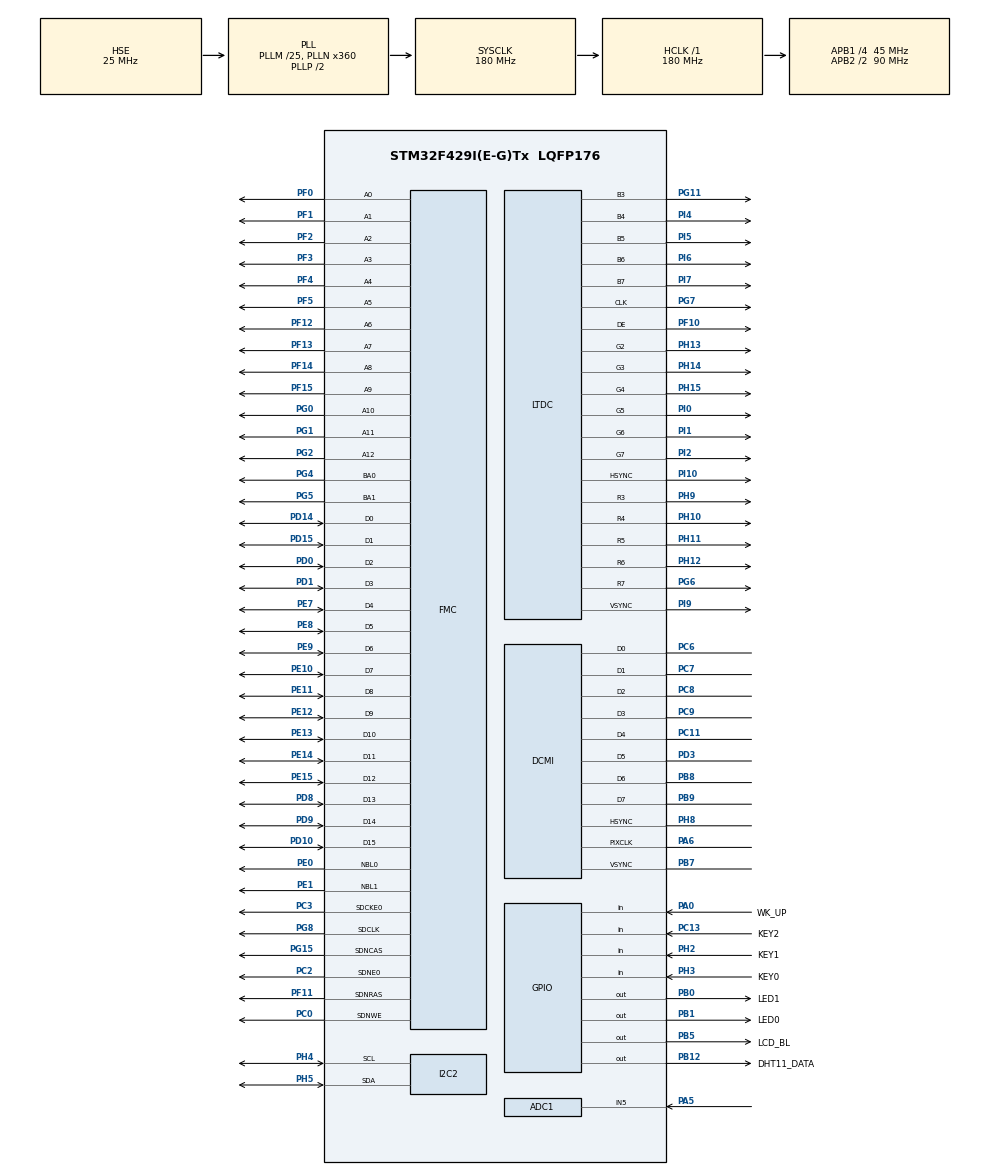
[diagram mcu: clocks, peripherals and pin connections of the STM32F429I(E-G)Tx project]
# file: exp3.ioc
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ADC1.Channel-1\#ChannelRegularConversion=ADC_CHANNEL_5
ADC1.NbrOfConversionFlag=1
ADC1.Rank-1\#ChannelRegularConversion=1
ADC1.SamplingTime-1\#ChannelRegularConversion=ADC_SAMPLETIME_480CYCLES
ADC1.master=1
DCMI.CaptureRate=DCMI_CR_ALL_FRAME
DCMI.HSPolarity=DCMI_HSPOLARITY_LOW
DCMI.PCKPolarity=DCMI_PCKPOLARITY_RISING
DCMI.VSPolarity=DCMI_VSPOLARITY_LOW
Dma.DCMI.0.Direction=DMA_PERIPH_TO_MEMORY
Dma.DCMI.0.FIFOMode=DMA_FIFOMODE_ENABLE
Dma.DCMI.0.FIFOThreshold=DMA_FIFO_THRESHOLD_FULL
Dma.DCMI.0.Instance=DMA2_Stream1
Dma.DCMI.0.MemBurst=DMA_MBURST_SINGLE
Dma.DCMI.0.MemDataAlignment=DMA_MDATAALIGN_HALFWORD
Dma.DCMI.0.MemInc=DMA_MINC_ENABLE
Dma.DCMI.0.Mode=DMA_CIRCULAR
Dma.DCMI.0.PeriphBurst=DMA_PBURST_SINGLE
Dma.DCMI.0.PeriphDataAlignment=DMA_PDATAALIGN_WORD
Dma.DCMI.0.PeriphInc=DMA_PINC_DISABLE
Dma.DCMI.0.Priority=DMA_PRIORITY_HIGH
Dma.Request0=DCMI
FMC.CASLatency1=FMC_SDRAM_CAS_LATENCY_2
FMC.ColumnBitsNumber1=FMC_SDRAM_COLUMN_BITS_NUM_9
FMC.ExitSelfRefreshDelay1=7
FMC.LoadToActiveDelay1=2
FMC.RCDDelay1=2
FMC.RPDelay1=2
FMC.ReadBurst1=FMC_SDRAM_RBURST_ENABLE
FMC.RowBitsNumber1=FMC_SDRAM_ROW_BITS_NUM_13
FMC.RowCycleDelay1=6
FMC.SDClockPeriod1=FMC_SDRAM_CLOCK_PERIOD_2
FMC.SelfRefreshTime1=6
FMC.WriteRecoveryTime1=4
LTDC.ActiveH=600
LTDC.ActiveW=1024
LTDC.Alpha_L0=255
LTDC.FBStartAdress_L0=0xC0000000
LTDC.HBP=140
LTDC.HFP=160
LTDC.HSync=20
LTDC.ImageHeight_L0=600
LTDC.ImageWidth_L0=1024
LTDC.Layers=0
LTDC.PCPolarity=LTDC_PCPOLARITY_IPC
LTDC.PixelFormat_L0=LTDC_PIXEL_FORMAT_RGB565
LTDC.VBP=20
LTDC.VFP=12
LTDC.VSync=3
LTDC.WindowX1_L0=1024
LTDC.WindowY1_L0=600
Mcu.Family=STM32F4
Mcu.Name=STM32F429I(E-G)Tx
Mcu.Package=LQFP176
NVIC.DCMI_IRQn=true\:2\:2\:false\:false\:true\:true\:true\:true
NVIC.DMA2_Stream1_IRQn=true\:1\:1\:false\:false\:true\:true\:true\:true
NVIC.PriorityGroup=NVIC_PRIORITYGROUP_4
PA0/WKUP.GPIO_Label=WK_UP
PA0/WKUP.GPIO_PuPd=GPIO_PULLDOWN
PA0/WKUP.Signal=GPIO_Input
PA13.Mode=Serial_Wire
PA13.Signal=SYS_JTMS-SWDIO
PA14.Mode=Serial_Wire
PA14.Signal=SYS_JTCK-SWCLK
PA5.Signal=ADCx_IN5
PA6.Mode=Slave_8_bits_External_Synchro
PA6.Signal=DCMI_PIXCLK
PB0.GPIO_Label=LED1
PB0.PinState=GPIO_PIN_SET
PB0.Signal=GPIO_Output
PB1.GPIO_Label=LED0
PB1.PinState=GPIO_PIN_SET
PB1.Signal=GPIO_Output
PB12.GPIO_Label=DHT11_DATA
PB12.GPIO_ModeDefaultOutputPP=GPIO_MODE_OUTPUT_OD
PB12.GPIO_PuPd=GPIO_NOPULL
PB12.GPIO_Speed=GPIO_SPEED_FREQ_HIGH
PB12.PinState=GPIO_PIN_SET
PB12.Signal=GPIO_Output
PB5.GPIO_Label=LCD_BL
PB5.PinState=GPIO_PIN_SET
PB5.Signal=GPIO_Output
PB7.Mode=Slave_8_bits_External_Synchro
PB7.Signal=DCMI_VSYNC
PB8.Mode=Slave_8_bits_External_Synchro
PB8.Signal=DCMI_D6
PB9.Mode=Slave_8_bits_External_Synchro
PB9.Signal=DCMI_D7
PC0.Signal=FMC_SDNWE
PC11.Mode=Slave_8_bits_External_Synchro
PC11.Signal=DCMI_D4
PC13.GPIO_Label=KEY2
PC13.GPIO_PuPd=GPIO_PULLUP
PC13.Signal=GPIO_Input
PC2.Mode=SdramChipSelect1_1
PC2.Signal=FMC_SDNE0
PC3.Mode=SdramChipSelect1_1
PC3.Signal=FMC_SDCKE0
PC6.Mode=Slave_8_bits_External_Synchro
PC6.Signal=DCMI_D0
PC7.Mode=Slave_8_bits_External_Synchro
PC7.Signal=DCMI_D1
PC8.Mode=Slave_8_bits_External_Synchro
PC8.Signal=DCMI_D2
PC9.Mode=Slave_8_bits_External_Synchro
PC9.Signal=DCMI_D3
PD0.Signal=FMC_D2_DA2
PD1.Signal=FMC_D3_DA3
PD10.Signal=FMC_D15_DA15
PD14.Signal=FMC_D0_DA0
PD15.Signal=FMC_D1_DA1
PD3.Mode=Slave_8_bits_External_Synchro
PD3.Signal=DCMI_D5
PD8.Signal=FMC_D13_DA13
PD9.Signal=FMC_D14_DA14
PE0.Signal=FMC_NBL0
PE1.Signal=FMC_NBL1
PE10.Signal=FMC_D7_DA7
PE11.Signal=FMC_D8_DA8
PE12.Signal=FMC_D9_DA9
PE13.Signal=FMC_D10_DA10
PE14.Signal=FMC_D11_DA11
PE15.Signal=FMC_D12_DA12
PE7.Signal=FMC_D4_DA4
PE8.Signal=FMC_D5_DA5
PE9.Signal=FMC_D6_DA6
PF0.Signal=FMC_A0
PF1.Signal=FMC_A1
PF10.Mode=RGB565
PF10.Signal=LTDC_DE
PF11.Signal=FMC_SDNRAS
PF12.Signal=FMC_A6
PF13.Signal=FMC_A7
PF14.Signal=FMC_A8
PF15.Signal=FMC_A9
PF2.Signal=FMC_A2
PF3.Signal=FMC_A3
PF4.Signal=FMC_A4
PF5.Signal=FMC_A5
PG0.Signal=FMC_A10
PG1.Signal=FMC_A11
PG11.Mode=RGB565
PG11.Signal=LTDC_B3
PG15.Signal=FMC_SDNCAS
PG2.Signal=FMC_A12
PG4.Signal=FMC_A14_BA0
PG5.Signal=FMC_A15_BA1
PG6.Mode=RGB565
PG6.Signal=LTDC_R7
PG7.Mode=RGB565
PG7.Signal=LTDC_CLK
PG8.Signal=FMC_SDCLK
PH0/OSC_IN.Mode=HSE-External-Oscillator
PH0/OSC_IN.Signal=RCC_OSC_IN
PH1/OSC_OUT.Mode=HSE-External-Oscillator
PH1/OSC_OUT.Signal=RCC_OSC_OUT
PH10.Mode=RGB565
PH10.Signal=LTDC_R4
PH11.Mode=RGB565
PH11.Signal=LTDC_R5
PH12.Mode=RGB565
PH12.Signal=LTDC_R6
PH13.Mode=RGB565
PH13.Signal=LTDC_G2
PH14.Mode=RGB565
PH14.Signal=LTDC_G3
PH15.Mode=RGB565
PH15.Signal=LTDC_G4
PH2.GPIO_Label=KEY1
PH2.GPIO_PuPd=GPIO_PULLUP
PH2.Signal=GPIO_Input
PH3.GPIO_Label=KEY0
PH3.GPIO_PuPd=GPIO_PULLUP
PH3.Signal=GPIO_Input
PH4.Mode=I2C
PH4.Signal=I2C2_SCL
PH5.Mode=I2C
PH5.Signal=I2C2_SDA
PH8.Mode=Slave_8_bits_External_Synchro
PH8.Signal=DCMI_HSYNC
PH9.Mode=RGB565
PH9.Signal=LTDC_R3
PI0.Mode=RGB565
PI0.Signal=LTDC_G5
PI1.Mode=RGB565
PI1.Signal=LTDC_G6
PI10.Mode=RGB565
PI10.Signal=LTDC_HSYNC
PI2.Mode=RGB565
PI2.Signal=LTDC_G7
PI4.Mode=RGB565
PI4.Signal=LTDC_B4
PI5.Mode=RGB565
PI5.Signal=LTDC_B5
PI6.Mode=RGB565
PI6.Signal=LTDC_B6
PI7.Mode=RGB565
PI7.Signal=LTDC_B7
PI9.Mode=RGB565
PI9.Signal=LTDC_VSYNC
ProjectManager.HeapSize=0x200
ProjectManager.StackSize=0x400
ProjectManager.TargetToolchain=STM32CubeIDE
RCC.48MHZClocksFreq_Value=90000000
RCC.AHBFreq_Value=180000000
RCC.APB1CLKDivider=RCC_HCLK_DIV4
RCC.APB1Freq_Value=45000000
RCC.APB1TimFreq_Value=90000000
RCC.APB2CLKDivider=RCC_HCLK_DIV2
RCC.APB2Freq_Value=90000000
RCC.APB2TimFreq_Value=180000000
RCC.CortexFreq_Value=180000000
RCC.HCLKFreq_Value=180000000
RCC.HSE_VALUE=25000000
RCC.HSI_VALUE=16000000
RCC.LSE_VALUE=32768
RCC.PLLM=25
RCC.PLLN=360
RCC.PLLSAIDivR=RCC_PLLSAIDIVR_4
RCC.PLLSAIN=360
RCC.PLLSAIR=2
RCC.PLLSourceVirtual=RCC_PLLSOURCE_HSE
RCC.SYSCLKFreq_VALUE=180000000
RCC.SYSCLKSource=RCC_SYSCLKSOURCE_PLLCLK
RCC.VCOOutputFreq_Value=360000000
SH.ADCx_IN5.0=ADC1_IN5,IN5
SH.FMC_A0.0=FMC_A0,13b-sda1
SH.FMC_A1.0=FMC_A1,13b-sda1
SH.FMC_A10.0=FMC_A10,13b-sda1
SH.FMC_A11.0=FMC_A11,13b-sda1
SH.FMC_A12.0=FMC_A12,13b-sda1
SH.FMC_A14_BA0.0=FMC_BA0,FourSdramBanks1
SH.FMC_A15_BA1.0=FMC_BA1,FourSdramBanks1
SH.FMC_A2.0=FMC_A2,13b-sda1
SH.FMC_A3.0=FMC_A3,13b-sda1
SH.FMC_A4.0=FMC_A4,13b-sda1
SH.FMC_A5.0=FMC_A5,13b-sda1
SH.FMC_A6.0=FMC_A6,13b-sda1
SH.FMC_A7.0=FMC_A7,13b-sda1
SH.FMC_A8.0=FMC_A8,13b-sda1
SH.FMC_A9.0=FMC_A9,13b-sda1
SH.FMC_D0_DA0.0=FMC_D0,sd-16b-d1
SH.FMC_D10_DA10.0=FMC_D10,sd-16b-d1
SH.FMC_D11_DA11.0=FMC_D11,sd-16b-d1
SH.FMC_D12_DA12.0=FMC_D12,sd-16b-d1
SH.FMC_D13_DA13.0=FMC_D13,sd-16b-d1
SH.FMC_D14_DA14.0=FMC_D14,sd-16b-d1
SH.FMC_D15_DA15.0=FMC_D15,sd-16b-d1
SH.FMC_D1_DA1.0=FMC_D1,sd-16b-d1
SH.FMC_D2_DA2.0=FMC_D2,sd-16b-d1
SH.FMC_D3_DA3.0=FMC_D3,sd-16b-d1
SH.FMC_D4_DA4.0=FMC_D4,sd-16b-d1
SH.FMC_D5_DA5.0=FMC_D5,sd-16b-d1
SH.FMC_D6_DA6.0=FMC_D6,sd-16b-d1
SH.FMC_D7_DA7.0=FMC_D7,sd-16b-d1
SH.FMC_D8_DA8.0=FMC_D8,sd-16b-d1
SH.FMC_D9_DA9.0=FMC_D9,sd-16b-d1
SH.FMC_NBL0.0=FMC_NBL0,Sd2ByteEnable1
SH.FMC_NBL1.0=FMC_NBL1,Sd2ByteEnable1
SH.FMC_SDCLK.0=FMC_SDCLK,13b-sda1
SH.FMC_SDNCAS.0=FMC_SDNCAS,13b-sda1
SH.FMC_SDNRAS.0=FMC_SDNRAS,13b-sda1
SH.FMC_SDNWE.0=FMC_SDNWE,13b-sda1
board=custom

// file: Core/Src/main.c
/* USER CODE BEGIN Header */
/**
  ******************************************************************************
  * @file           : main.c
  * @brief          : Main program body
  ******************************************************************************
  * @attention
  *
  * Copyright (c) 2026 STMicroelectronics.
  * All rights reserved.
  *
  * This software is licensed under terms that can be found in the LICENSE file
  * in the root directory of this software component.
  * If no LICENSE file comes with this software, it is provided AS-IS.
  *
  ******************************************************************************
  */
/* USER CODE END Header */
#include "main.h"

/* USER CODE BEGIN Includes */
#include "lcd.h"
#include "lcd_ui.h"
#include "dht11.h"
#include "adc_volt.h"
#include "key.h"
#include "alert.h"
#include "camera.h"
/* USER CODE END Includes */

ADC_HandleTypeDef hadc1;

DCMI_HandleTypeDef hdcmi;
DMA_HandleTypeDef hdma_dcmi;

I2C_HandleTypeDef hi2c2;

LTDC_HandleTypeDef hltdc;

SDRAM_HandleTypeDef hsdram1;

/* USER CODE BEGIN PV */
static dht11_data_t g_dht;          /* DHT11 温湿度(整数/小数分离) */
static uint8_t      g_dht_ok = 0;   /* 最近一次 DHT11 读取是否成功 */
static uint8_t      g_page   = 0;   /* 0=首页, 1=摄像头预览 */
static uint8_t      g_cam_ok = 0;   /* 摄像头初始化是否成功 */
/* USER CODE END PV */

void SystemClock_Config(void);
static void MX_GPIO_Init(void);
static void MX_DMA_Init(void);
static void MX_DCMI_Init(void);
static void MX_I2C2_Init(void);
static void MX_FMC_Init(void);
static void MX_ADC1_Init(void);
static void MX_LTDC_Init(void);

int main(void)
{

  /* MCU Configuration--------------------------------------------------------*/

  /* Reset of all peripherals, Initializes the Flash interface and the Systick. */
  HAL_Init();

  /* Configure the system clock */
  SystemClock_Config();

  /* Initialize all configured peripherals */
  MX_GPIO_Init();
  MX_DMA_Init();
  MX_DCMI_Init();
  MX_I2C2_Init();
  MX_FMC_Init();
  MX_ADC1_Init();
  MX_LTDC_Init();
  /* USER CODE BEGIN 2 */
  /* ===== 初始化所有模块 ===== */
  lcd_init();                       /* 点亮背光 + 清屏 */
  dht11_init();
  adc_volt_init();
  key_init();
  alert_init();

  lcd_ui_init();                    /* 画首页固定文字(标题/设备标识/标签) */

  /* 摄像头初始化(失败不影响首页); 采集在切到摄像头页时启动 */
  g_cam_ok = (camera_init() == CAM_ERR_NONE);
  /* USER CODE END 2 */

  /* Infinite loop */
  while (1)
  {

    /* USER CODE BEGIN 3 */
    uint8_t key = key_scan();

    /* KEY0 切页 */
    if (key == KEY0)
    {
        g_page = !g_page;
        if (g_page)
        {
            /* 进入摄像头页: 启动采集, 画面逐行自动写入 LCD */
            if (g_cam_ok)
            {
                camera_start();
            }
            else
            {
                lcd_clear(WHITE);
                /* 故障提示用 ASCII: 中文字库只含界面固定用语, 写中文会因缺字而整行空白 */
                lcd_show_string(376, 200, 32, (char *)"CAMERA INIT FAILED", RED);
            }
        }
        else
        {
            camera_stop();          /* 停止采集, 避免覆盖首页 */
            lcd_ui_init();          /* 回到首页, 重画固定文字 */
        }
    }

    if (g_page == 0)
    {
        /* ===== 首页: 温湿度 + 电压 + 预警 ===== */
        uint32_t mv;
        uint16_t raw;
        static uint32_t last_dht = 0;

        /* DHT11 约 1s 读一次(采样间隔要求 >=1s) */
        if (HAL_GetTick() - last_dht >= 1000)
        {
            last_dht = HAL_GetTick();
            g_dht_ok = (dht11_read(&g_dht) == 0);
        }

        /* ADC 电压(取 8 次平均) */
        raw = adc_volt_raw_avg(8);
        mv  = adc_volt_mv(raw);

        /* 阈值预警: temp/humi 转 0.1 度/0.1%RH 整数 */
        int16_t t10 = (int16_t)(g_dht.temp_int * 10 + g_dht.temp_dec);
        int16_t h10 = (int16_t)(g_dht.humi_int * 10 + g_dht.humi_dec);
        alert_poll(t10, g_dht_ok, h10, g_dht_ok, mv, 1);

        /* 刷新首页数值区(局部刷新, 不闪) */
        {
            static char cam_stat[16];
            if (g_cam_ok) {
                cam_stat[0] = 'O'; cam_stat[1] = 'K'; cam_stat[2] = 0;
            } else if (g_cam_err == 2) {
                /* F2: 完整诊断串 "P<PCF> D<diag> I<id>"
                 *   P: PCF8574 读回值(FB=成功拉低PWDN, FF=未拉低, EE=读失败)
                 *   D: SCCB诊断(bit0=空闲SCL高,bit1=空闲SDA高,bit2=地址有ACK)
                 *   I: 读回的 OV5640 ID(应=5640) */
                static const char hex[] = "0123456789ABCDEF";
                cam_stat[0] = 'P';
                cam_stat[1] = hex[(g_cam_pcf >> 4) & 0xF];
                cam_stat[2] = hex[g_cam_pcf & 0xF];
                cam_stat[3] = ' ';
                cam_stat[4] = 'D';
                cam_stat[5] = '0' + (g_sccb_diag & 0x07);
                cam_stat[6] = ' ';
                cam_stat[7] = 'I';
                cam_stat[8]  = hex[(g_cam_id >> 12) & 0xF];
                cam_stat[9]  = hex[(g_cam_id >> 8) & 0xF];
                cam_stat[10] = hex[(g_cam_id >> 4) & 0xF];
                cam_stat[11] = hex[g_cam_id & 0xF];
                cam_stat[12] = 0;
            } else {
                cam_stat[0] = 'F'; cam_stat[1] = '0' + g_cam_err; cam_stat[2] = 0;
            }
            lcd_ui_update(g_dht_ok ? &g_dht : 0, mv, raw,
                          g_dht_ok, cam_stat, alert_get());
        }

        HAL_Delay(100);
    }
    else
    {
        /* ===== 摄像头预览页 ===== */
        HAL_Delay(50);
    }
  }
  /* USER CODE END 3 */
}

void SystemClock_Config(void)
{
  RCC_OscInitTypeDef RCC_OscInitStruct = {0};
  RCC_ClkInitTypeDef RCC_ClkInitStruct = {0};

  /** Configure the main internal regulator output voltage
  */
  __HAL_RCC_PWR_CLK_ENABLE();
  __HAL_PWR_VOLTAGESCALING_CONFIG(PWR_REGULATOR_VOLTAGE_SCALE1);

  /** Initializes the RCC Oscillators according to the specified parameters
  * in the RCC_OscInitTypeDef structure.
  */
  RCC_OscInitStruct.OscillatorType = RCC_OSCILLATORTYPE_HSE;
  RCC_OscInitStruct.HSEState = RCC_HSE_ON;
  RCC_OscInitStruct.PLL.PLLState = RCC_PLL_ON;
  RCC_OscInitStruct.PLL.PLLSource = RCC_PLLSOURCE_HSE;
  RCC_OscInitStruct.PLL.PLLM = 25;
  RCC_OscInitStruct.PLL.PLLN = 360;
  RCC_OscInitStruct.PLL.PLLP = RCC_PLLP_DIV2;
  RCC_OscInitStruct.PLL.PLLQ = 4;
  if (HAL_RCC_OscConfig(&RCC_OscInitStruct) != HAL_OK)
  {
    Error_Handler();
  }

  /** Activate the Over-Drive mode
  */
  if (HAL_PWREx_EnableOverDrive() != HAL_OK)
  {
    Error_Handler();
  }

  /** Initializes the CPU, AHB and APB buses clocks
  */
  RCC_ClkInitStruct.ClockType = RCC_CLOCKTYPE_HCLK|RCC_CLOCKTYPE_SYSCLK
                              |RCC_CLOCKTYPE_PCLK1|RCC_CLOCKTYPE_PCLK2;
  RCC_ClkInitStruct.SYSCLKSource = RCC_SYSCLKSOURCE_PLLCLK;
  RCC_ClkInitStruct.AHBCLKDivider = RCC_SYSCLK_DIV1;
  RCC_ClkInitStruct.APB1CLKDivider = RCC_HCLK_DIV4;
  RCC_ClkInitStruct.APB2CLKDivider = RCC_HCLK_DIV2;

  if (HAL_RCC_ClockConfig(&RCC_ClkInitStruct, FLASH_LATENCY_5) != HAL_OK)
  {
    Error_Handler();
  }
}

static void MX_ADC1_Init(void)
{

  ADC_ChannelConfTypeDef sConfig = {0};

  /** Configure the global features of the ADC (Clock, Resolution, Data Alignment and number of conversion)
  */
  hadc1.Instance = ADC1;
  hadc1.Init.ClockPrescaler = ADC_CLOCK_SYNC_PCLK_DIV4;
  hadc1.Init.Resolution = ADC_RESOLUTION_12B;
  hadc1.Init.ScanConvMode = DISABLE;
  hadc1.Init.ContinuousConvMode = DISABLE;
  hadc1.Init.DiscontinuousConvMode = DISABLE;
  hadc1.Init.ExternalTrigConvEdge = ADC_EXTERNALTRIGCONVEDGE_NONE;
  hadc1.Init.ExternalTrigConv = ADC_SOFTWARE_START;
  hadc1.Init.DataAlign = ADC_DATAALIGN_RIGHT;
  hadc1.Init.NbrOfConversion = 1;
  hadc1.Init.DMAContinuousRequests = DISABLE;
  hadc1.Init.EOCSelection = ADC_EOC_SINGLE_CONV;
  if (HAL_ADC_Init(&hadc1) != HAL_OK)
  {
    Error_Handler();
  }

  /** Configure for the selected ADC regular channel its corresponding rank in the sequencer and its sample time.
  */
  sConfig.Channel = ADC_CHANNEL_5;
  sConfig.Rank = 1;
  sConfig.SamplingTime = ADC_SAMPLETIME_480CYCLES;
  if (HAL_ADC_ConfigChannel(&hadc1, &sConfig) != HAL_OK)
  {
    Error_Handler();
  }
  /* USER CODE BEGIN ADC1_Init 2 */
  /* 采样时间改回 480 周期: 电位�?(RV1)输出阻抗较高, 默认 3 周期采样时间太短, 读数会明显偏�? */
  sConfig.SamplingTime = ADC_SAMPLETIME_480CYCLES;
  if (HAL_ADC_ConfigChannel(&hadc1, &sConfig) != HAL_OK)
  {
    Error_Handler();
  }
  /* USER CODE END ADC1_Init 2 */

}

static void MX_DCMI_Init(void)
{

  hdcmi.Instance = DCMI;
  hdcmi.Init.SynchroMode = DCMI_SYNCHRO_HARDWARE;
  hdcmi.Init.PCKPolarity = DCMI_PCKPOLARITY_RISING;
  hdcmi.Init.VSPolarity = DCMI_VSPOLARITY_LOW;
  hdcmi.Init.HSPolarity = DCMI_HSPOLARITY_LOW;
  hdcmi.Init.CaptureRate = DCMI_CR_ALL_FRAME;
  hdcmi.Init.ExtendedDataMode = DCMI_EXTEND_DATA_8B;
  hdcmi.Init.JPEGMode = DCMI_JPEG_DISABLE;
  if (HAL_DCMI_Init(&hdcmi) != HAL_OK)
  {
    Error_Handler();
  }

}

static void MX_I2C2_Init(void)
{

  hi2c2.Instance = I2C2;
  hi2c2.Init.ClockSpeed = 100000;
  hi2c2.Init.DutyCycle = I2C_DUTYCYCLE_2;
  hi2c2.Init.OwnAddress1 = 0;
  hi2c2.Init.AddressingMode = I2C_ADDRESSINGMODE_7BIT;
  hi2c2.Init.DualAddressMode = I2C_DUALADDRESS_DISABLE;
  hi2c2.Init.OwnAddress2 = 0;
  hi2c2.Init.GeneralCallMode = I2C_GENERALCALL_DISABLE;
  hi2c2.Init.NoStretchMode = I2C_NOSTRETCH_DISABLE;
  if (HAL_I2C_Init(&hi2c2) != HAL_OK)
  {
    Error_Handler();
  }

  /** Configure Analogue filter
  */
  if (HAL_I2CEx_ConfigAnalogFilter(&hi2c2, I2C_ANALOGFILTER_ENABLE) != HAL_OK)
  {
    Error_Handler();
  }

  /** Configure Digital filter
  */
  if (HAL_I2CEx_ConfigDigitalFilter(&hi2c2, 0) != HAL_OK)
  {
    Error_Handler();
  }

}

static void MX_LTDC_Init(void)
{

  LTDC_LayerCfgTypeDef pLayerCfg = {0};

  hltdc.Instance = LTDC;
  hltdc.Init.HSPolarity = LTDC_HSPOLARITY_AL;
  hltdc.Init.VSPolarity = LTDC_VSPOLARITY_AL;
  hltdc.Init.DEPolarity = LTDC_DEPOLARITY_AL;
  hltdc.Init.PCPolarity = LTDC_PCPOLARITY_IPC;
  hltdc.Init.HorizontalSync = 19;
  hltdc.Init.VerticalSync = 2;
  hltdc.Init.AccumulatedHBP = 159;
  hltdc.Init.AccumulatedVBP = 22;
  hltdc.Init.AccumulatedActiveW = 1183;
  hltdc.Init.AccumulatedActiveH = 622;
  hltdc.Init.TotalWidth = 1343;
  hltdc.Init.TotalHeigh = 634;
  hltdc.Init.Backcolor.Blue = 0;
  hltdc.Init.Backcolor.Green = 0;
  hltdc.Init.Backcolor.Red = 0;
  if (HAL_LTDC_Init(&hltdc) != HAL_OK)
  {
    Error_Handler();
  }
  pLayerCfg.WindowX0 = 0;
  pLayerCfg.WindowX1 = 1024;
  pLayerCfg.WindowY0 = 0;
  pLayerCfg.WindowY1 = 600;
  pLayerCfg.PixelFormat = LTDC_PIXEL_FORMAT_RGB565;
  pLayerCfg.Alpha = 255;
  pLayerCfg.Alpha0 = 0;
  pLayerCfg.BlendingFactor1 = LTDC_BLENDING_FACTOR1_CA;
  pLayerCfg.BlendingFactor2 = LTDC_BLENDING_FACTOR2_CA;
  pLayerCfg.FBStartAdress = 0xC0000000;
  pLayerCfg.ImageWidth = 1024;
  pLayerCfg.ImageHeight = 600;
  pLayerCfg.Backcolor.Blue = 0;
  pLayerCfg.Backcolor.Green = 0;
  pLayerCfg.Backcolor.Red = 0;
  if (HAL_LTDC_ConfigLayer(&hltdc, &pLayerCfg, 0) != HAL_OK)
  {
    Error_Handler();
  }

}

static void MX_DMA_Init(void)
{

  /* DMA controller clock enable */
  __HAL_RCC_DMA2_CLK_ENABLE();

  /* DMA interrupt init */
  /* DMA2_Stream1_IRQn interrupt configuration */
  HAL_NVIC_SetPriority(DMA2_Stream1_IRQn, 1, 1);
  HAL_NVIC_EnableIRQ(DMA2_Stream1_IRQn);

}

/* FMC initialization function */
static void MX_FMC_Init(void)
{

  FMC_SDRAM_TimingTypeDef SdramTiming = {0};

  /** Perform the SDRAM1 memory initialization sequence
  */
  hsdram1.Instance = FMC_SDRAM_DEVICE;
  /* hsdram1.Init */
  hsdram1.Init.SDBank = FMC_SDRAM_BANK1;
  hsdram1.Init.ColumnBitsNumber = FMC_SDRAM_COLUMN_BITS_NUM_9;
  hsdram1.Init.RowBitsNumber = FMC_SDRAM_ROW_BITS_NUM_13;
  hsdram1.Init.MemoryDataWidth = FMC_SDRAM_MEM_BUS_WIDTH_16;
  hsdram1.Init.InternalBankNumber = FMC_SDRAM_INTERN_BANKS_NUM_4;
  hsdram1.Init.CASLatency = FMC_SDRAM_CAS_LATENCY_2;
  hsdram1.Init.WriteProtection = FMC_SDRAM_WRITE_PROTECTION_DISABLE;
  hsdram1.Init.SDClockPeriod = FMC_SDRAM_CLOCK_PERIOD_2;
  hsdram1.Init.ReadBurst = FMC_SDRAM_RBURST_ENABLE;
  hsdram1.Init.ReadPipeDelay = FMC_SDRAM_RPIPE_DELAY_0;
  /* SdramTiming */
  SdramTiming.LoadToActiveDelay = 2;
  SdramTiming.ExitSelfRefreshDelay = 7;
  SdramTiming.SelfRefreshTime = 6;
  SdramTiming.RowCycleDelay = 6;
  SdramTiming.WriteRecoveryTime = 4;
  SdramTiming.RPDelay = 2;
  SdramTiming.RCDDelay = 2;

  if (HAL_SDRAM_Init(&hsdram1, &SdramTiming) != HAL_OK)
  {
    Error_Handler( );
  }

  /* USER CODE BEGIN FMC_Init 2 */
  /* SDRAM 初始化命令序�?(必需, CubeMX 不生�?) —�?? 缺这�?�? SDRAM 无法读写, 屏幕会全�? */
  {
    FMC_SDRAM_CommandTypeDef Command = {0};

    /* 1. 时钟配置使能, 之后至少延时 200us(此处 1ms) */
    Command.CommandMode            = FMC_SDRAM_CMD_CLK_ENABLE;
    Command.CommandTarget          = FMC_SDRAM_CMD_TARGET_BANK1;
    Command.AutoRefreshNumber      = 1;
    Command.ModeRegisterDefinition = 0;
    HAL_SDRAM_SendCommand(&hsdram1, &Command, 0x1000);
    HAL_Delay(1);

    /* 2. 对所有存储区预充�? */
    Command.CommandMode            = FMC_SDRAM_CMD_PALL;
    HAL_SDRAM_SendCommand(&hsdram1, &Command, 0x1000);

    /* 3. 自动刷新 8 �? */
    Command.CommandMode            = FMC_SDRAM_CMD_AUTOREFRESH_MODE;
    Command.AutoRefreshNumber      = 8;
    HAL_SDRAM_SendCommand(&hsdram1, &Command, 0x1000);

    /* 4. 加载模式寄存�?: bit9=1(写突发单�?), bit6~4=010(CAS=2) */
    Command.CommandMode            = FMC_SDRAM_CMD_LOAD_MODE;
    Command.AutoRefreshNumber      = 1;
    Command.ModeRegisterDefinition = 0x220;
    HAL_SDRAM_SendCommand(&hsdram1, &Command, 0x1000);

    /* 5. 设置刷新频率(计数器�?? 730, 对应�? 64ms/8192 �?) */
    HAL_SDRAM_ProgramRefreshRate(&hsdram1, 730);
  }
  /* USER CODE END FMC_Init 2 */
}

static void MX_GPIO_Init(void)
{
  GPIO_InitTypeDef GPIO_InitStruct = {0};

  /* GPIO Ports Clock Enable */
  __HAL_RCC_GPIOC_CLK_ENABLE();
  __HAL_RCC_GPIOI_CLK_ENABLE();
  __HAL_RCC_GPIOF_CLK_ENABLE();
  __HAL_RCC_GPIOH_CLK_ENABLE();
  __HAL_RCC_GPIOA_CLK_ENABLE();
  __HAL_RCC_GPIOB_CLK_ENABLE();
  __HAL_RCC_GPIOG_CLK_ENABLE();
  __HAL_RCC_GPIOE_CLK_ENABLE();
  __HAL_RCC_GPIOD_CLK_ENABLE();

  /*Configure GPIO pin Output Level */
  HAL_GPIO_WritePin(GPIOB, LED1_Pin|LED0_Pin|DHT11_DATA_Pin|LCD_BL_Pin, GPIO_PIN_SET);

  /*Configure GPIO pin : KEY2_Pin */
  GPIO_InitStruct.Pin = KEY2_Pin;
  GPIO_InitStruct.Mode = GPIO_MODE_INPUT;
  GPIO_InitStruct.Pull = GPIO_PULLUP;
  HAL_GPIO_Init(KEY2_GPIO_Port, &GPIO_InitStruct);

  /*Configure GPIO pin : WK_UP_Pin */
  GPIO_InitStruct.Pin = WK_UP_Pin;
  GPIO_InitStruct.Mode = GPIO_MODE_INPUT;
  GPIO_InitStruct.Pull = GPIO_PULLDOWN;
  HAL_GPIO_Init(WK_UP_GPIO_Port, &GPIO_InitStruct);

  /*Configure GPIO pins : KEY1_Pin KEY0_Pin */
  GPIO_InitStruct.Pin = KEY1_Pin|KEY0_Pin;
  GPIO_InitStruct.Mode = GPIO_MODE_INPUT;
  GPIO_InitStruct.Pull = GPIO_PULLUP;
  HAL_GPIO_Init(GPIOH, &GPIO_InitStruct);

  /*Configure GPIO pins : LED1_Pin LED0_Pin LCD_BL_Pin */
  GPIO_InitStruct.Pin = LED1_Pin|LED0_Pin|LCD_BL_Pin;
  GPIO_InitStruct.Mode = GPIO_MODE_OUTPUT_PP;
  GPIO_InitStruct.Pull = GPIO_NOPULL;
  GPIO_InitStruct.Speed = GPIO_SPEED_FREQ_LOW;
  HAL_GPIO_Init(GPIOB, &GPIO_InitStruct);

  /*Configure GPIO pin : DHT11_DATA_Pin */
  GPIO_InitStruct.Pin = DHT11_DATA_Pin;
  GPIO_InitStruct.Mode = GPIO_MODE_OUTPUT_OD;
  GPIO_InitStruct.Pull = GPIO_NOPULL;
  GPIO_InitStruct.Speed = GPIO_SPEED_FREQ_HIGH;
  HAL_GPIO_Init(DHT11_DATA_GPIO_Port, &GPIO_InitStruct);

}

/* USER CODE BEGIN 4 */
/* DCMI 帧完成回调(阶段六摄像头预览用): 转发给 camera 模块 */
void HAL_DCMI_FrameEventCallback(DCMI_HandleTypeDef *hdcmi_)
{
    (void)hdcmi_;
    camera_on_frame();
}
/* USER CODE END 4 */

void Error_Handler(void)
{
  __disable_irq();
  while (1)
  {
  }
}
